# GD32E501 register map
File version: 1.0
CPU: CM33 r0p4, little endian, MPU, FPU, 4 interrupt priority bits
Registers are 32-bit, read-write, reset 0x0 unless marked. A register's access mark holds for its fields unless they carry their own. Offsets are from the block's base; [hi:lo] are bit positions; {n}, {i} and the like mark numbered series.

## CLA — Configurable Logic Array unit
Base 0x40038000
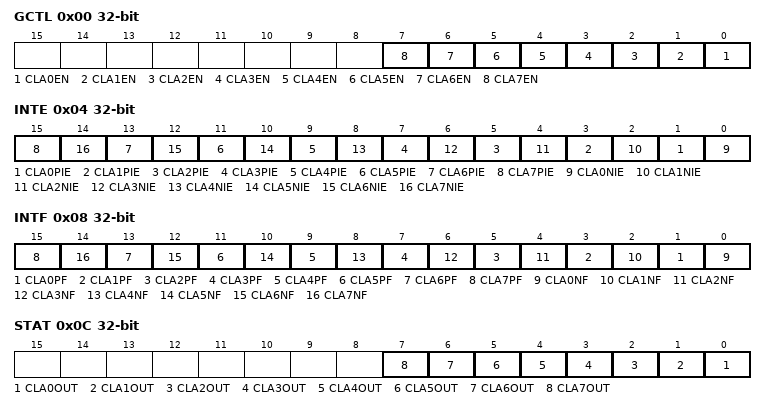
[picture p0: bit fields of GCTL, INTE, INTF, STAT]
0x00 GCTL — Global control register
  [n] CLA{n}EN (n=0..7) — CLA{n} uint enable
0x04 INTE — Interrupt flag enable register
  [2n+1] CLA{n}PIE (n=0..7) — CLA{n} unit posedge interrupt enable
  [2n] CLA{n}NIE (n=0..7) — CLA{n} unit negedge interrupt enable
0x08 INTF — Interrupt flag register
  [2n+1] CLA{n}PF (n=0..7) — CLA{n} unit posegde flag
  [2n] CLA{n}NF (n=0..7) — CLA{n} unit negegde flag
0x0C STAT ro — Status Register
  [n] CLA{n}OUT (n=0..7) — CLA{n} unit output state
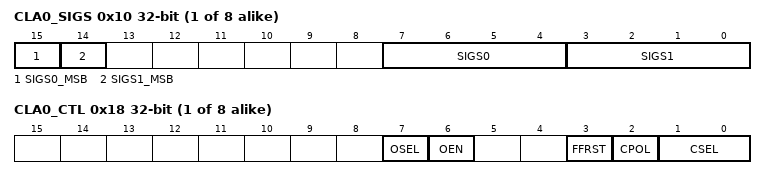
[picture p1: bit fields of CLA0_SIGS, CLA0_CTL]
{0x10+0xC*i} CLA{i}_SIGS (i=0..7) — Multiplexer selection register
  [15] SIGS0_MSB — multiplexer 0 input selection
  [14] SIGS1_MSB — multiplexer 1 input selection
  [7:4] SIGS0 — multiplexer 0 input selection
  [3:0] SIGS1 — multiplexer 1 input selection
0x14 CLA0_LCUCTL — LCU control register
  [7:0] LCUCTL
{0x18+0xC*i} CLA{i}_CTL access per field (i=0..7) — control register
  [7] OSEL rw — output selection
  [6] OEN rw — output enable
  [3] FFRST wo — Flip-flop output reset
  [2] CPOL rw — Clock polarity
  [1:0] CSEL rw — Clock selection
0x20 CLA1_LCUCTL — LCU control register
  [7:0] LCUCTL
0x2C CLA2_LCUC — LCU control register
  [7:0] LCUCTL
{0x14+0xC*i} CLA{i}_LCUCTL (i=3..7) — LCU control register
  [7:0] LCUCTL

## CMP — Comparator
Base 0x4001001C
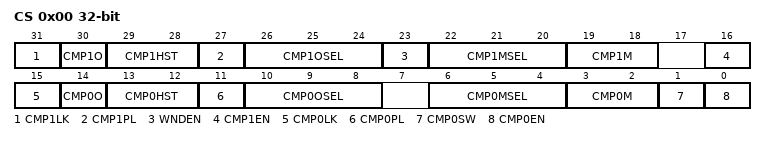
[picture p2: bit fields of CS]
0x00 CS access per field — control and status register
  [31] CMP1LK rw — Comparator 1 lock
  [30] CMP1O ro — Comparator 1 output
  [29:28] CMP1HST rw — Comparator 1 hysteresis
  [27] CMP1PL rw — Polarity of comparator 1 output
  [26:24] CMP1OSEL rw — Comparator 1 output selection
  [23] WNDEN rw — Window mode enable
  [22:20] CMP1MSEL rw — Comparator 0 input selection
  [19:18] CMP1M rw — Comparator 1 mode
  [16] CMP1EN rw — Comparator 1 enable
  [15] CMP0LK rw — Comparator 0 lock
  [14] CMP0O ro — Comparator 0 output
  [13:12] CMP0HST rw — Comparator 0 hysteresis
  [11] CMP0PL rw — Polarity of comparator 0 output
  [10:8] CMP0OSEL rw — Comparator 0 output selection
  [6:4] CMP0MSEL rw — Comparator 0 input selection
  [3:2] CMP0M rw — Comparator 0 mode
  [1] CMP0SW rw — Comparator 0 switch
  [0] CMP0EN rw — Comparator 0 enable

## CRC — cyclic redundancy check calculation unit
Base 0x40023000
0x00 DATA reset 0xFFFFFFFF
  [31:0] DATA — CRC calculation result bits
0x04 FDATA — Free data register
  [7:0] FDATA — General-purpose 8-bit data register bits
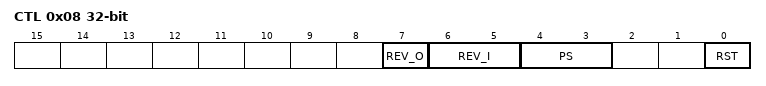
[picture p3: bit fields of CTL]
0x08 CTL — Control register
  [7] REV_O — Reverse output data
  [6:5] REV_I — Reverse input data
  [4:3] PS — Size of polynomial
  [0] RST — reset bit
0x10 IDATA reset 0xFFFFFFFF — Initialization Data Register
  [31:0] IDATA — CRC calculation initial value
0x14 POLY reset 0x4C11DB7 — Polynomial register
  [31:0] POLY — User configurable polynomial value

## DAC0 — Digital-to-analog converter
Base 0x40007400
Same registers: DAC1 0x4000CC00, DAC2 0x4000D000, DAC3 0x4000D400
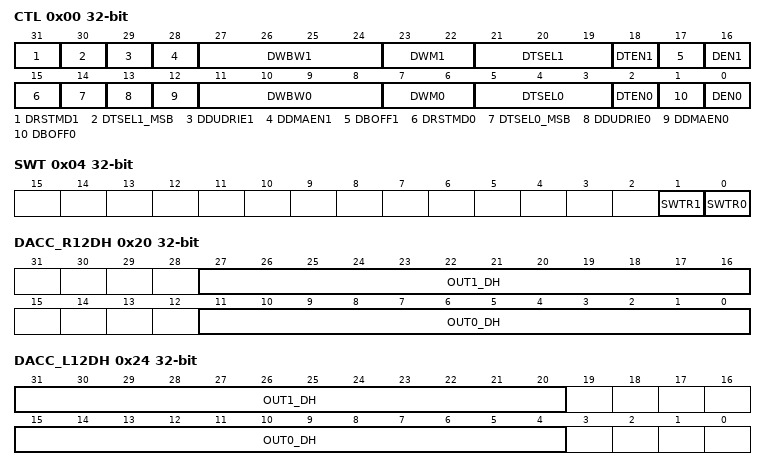
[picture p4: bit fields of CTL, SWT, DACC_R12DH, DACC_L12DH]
0x00 CTL — control register
  [31] DRSTMD1 — DAC1 Reset mode
  [30] DTSEL1_MSB — DAC1 Trigger selection bit3
  [29] DDUDRIE1 — DAC1 DMA underrun interrupt enable
  [28] DDMAEN1 — DAC1 DMA enable
  [27:24] DWBW1 — DAC1 noise wave bit width
  [23:22] DWM1 — DAC1 noise wave mode
  [21:19] DTSEL1 — DAC1 trigger selection
  [18] DTEN1 — DAC1 trigger enable
  [17] DBOFF1 — DAC1 output buffer turn off
  [16] DEN1 — DAC1 enable
  [15] DRSTMD0 — DAC0 Reset mode
  [14] DTSEL0_MSB — DAC0 Trigger selection bit3
  [13] DDUDRIE0 — DAC0 DMA underrun interrupt enable
  [12] DDMAEN0 — DAC0 DMA enable
  [11:8] DWBW0 — DAC0 noise wave bit width
  [7:6] DWM0 — DAC0 noise wave mode
  [5:3] DTSEL0 — DAC0 trigger selection
  [2] DTEN0 — DAC0 trigger enable
  [1] DBOFF0 — DAC0 output buffer turn off
  [0] DEN0 — DAC0 enable
0x04 SWT wo — software trigger register
  [1] SWTR1 — DAC1 software trigger
  [0] SWTR0 — DAC0 software trigger
0x08 OUT0_R12DH — DAC_OUT0 12-bit right-aligned data holding register
  [11:0] OUT0_DH — DACx_OUT0 12-bit right-aligned data
0x0C OUT0_L12DH — DAC_OUT0 12-bit left-aligned data holding register
  [15:4] OUT0_DH — DACx_OUT0 12-bit left-aligned data
0x10 OUT0_R8DH — DAC_OUT0 8-bit right aligned data holding register
  [7:0] OUT0_DH — DAC0 8-bit right-aligned data
0x14 OUT1_R12DH — DAC_OUT1 12-bit right-aligned data holding register
  [11:0] OUT1_DH — DACx_OUT1 12-bit right-aligned data
0x18 OUT1_L12DH — DAC_OUT1 12-bit left aligned data holding register
  [15:4] OUT1_DH — DACx_OUT1 12-bit left-aligned data
0x1C OUT1_R8DH — DACx_OUT1 8-bit right aligned data holding register
  [7:0] OUT1_DH — DACx_OUT1 8-bit right-aligned data
0x20 DACC_R12DH — DAC concurrent mode 12-bit right-aligned data holding register
  [27:16] OUT1_DH — DACx_OUT1 12-bit right-aligned data
  [11:0] OUT0_DH — DACx_OUT0 12-bit right-aligned data
0x24 DACC_L12DH — DAC concurrent mode 12-bit left aligned data holding register
  [31:20] OUT1_DH — DACx_OUT1 12-bit left-aligned data
  [15:4] OUT0_DH — DACx_OUT0 12-bit left-aligned data
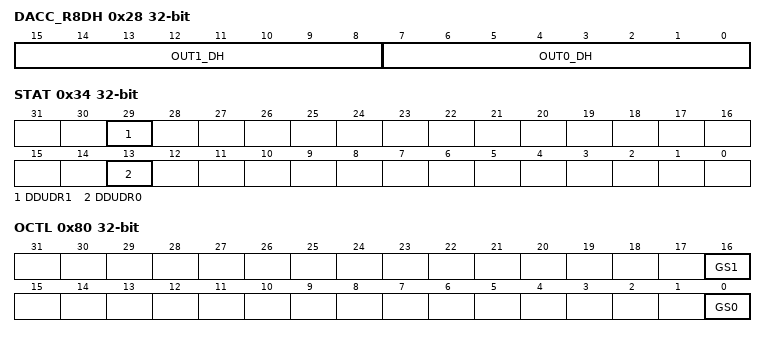
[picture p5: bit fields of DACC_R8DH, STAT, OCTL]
0x28 DACC_R8DH — DAC concurrent mode 8-bit right aligned data holding register
  [15:8] OUT1_DH — DACx_OUT1 8-bit right-aligned data
  [7:0] OUT0_DH — DACx_OUT0 8-bit right-aligned data
0x2C OUT0_DO ro — DAC_OUT0 data output register
  [11:0] OUT0_DO — DACx_OUT0 data output
0x30 OUT1_DO ro — DAC_OUT1 data output register
  [11:0] OUT1_DO — DACx_OUT1 data output
0x34 STAT — DAC status register
  [29] DDUDR1 — DACx_OUT1 DMA underrun flag
  [13] DDUDR0 — DACx_OUT0 DMA underrun flag
0x80 OCTL — DAC output control register
  [16] GS1 — DACx_OUT1 output buffer g ain selection
  [0] GS0 — DACx_OUT0 output buffer Gain selection
